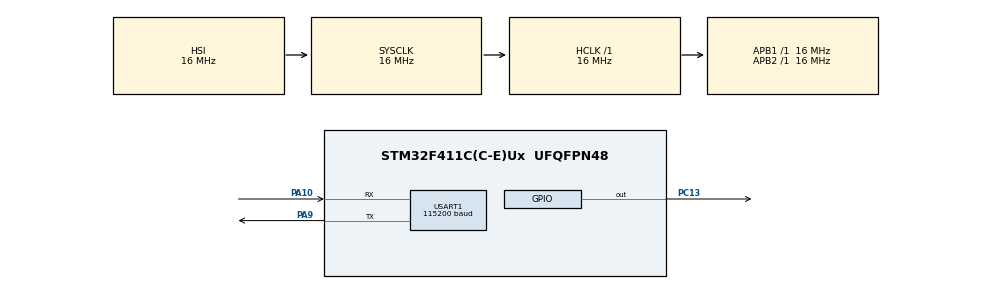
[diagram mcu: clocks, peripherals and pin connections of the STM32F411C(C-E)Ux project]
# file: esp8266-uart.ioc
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Dma.Request0=USART1_TX
Dma.USART1_TX.0.Direction=DMA_MEMORY_TO_PERIPH
Dma.USART1_TX.0.FIFOMode=DMA_FIFOMODE_DISABLE
Dma.USART1_TX.0.Instance=DMA2_Stream7
Dma.USART1_TX.0.MemDataAlignment=DMA_MDATAALIGN_BYTE
Dma.USART1_TX.0.MemInc=DMA_MINC_ENABLE
Dma.USART1_TX.0.Mode=DMA_CIRCULAR
Dma.USART1_TX.0.PeriphDataAlignment=DMA_PDATAALIGN_BYTE
Dma.USART1_TX.0.PeriphInc=DMA_PINC_DISABLE
Dma.USART1_TX.0.Priority=DMA_PRIORITY_LOW
Mcu.Family=STM32F4
Mcu.Name=STM32F411C(C-E)Ux
Mcu.Package=UFQFPN48
NVIC.DMA2_Stream7_IRQn=true\:0\:0\:false\:false\:true\:false\:true\:true
NVIC.PriorityGroup=NVIC_PRIORITYGROUP_4
NVIC.USART1_IRQn=true\:0\:0\:false\:false\:true\:true\:true\:true
PA10.Mode=Asynchronous
PA10.Signal=USART1_RX
PA9.Mode=Asynchronous
PA9.Signal=USART1_TX
PC13-ANTI_TAMP.PinState=GPIO_PIN_SET
PC13-ANTI_TAMP.Signal=GPIO_Output
ProjectManager.HeapSize=0x200
ProjectManager.StackSize=0x400
ProjectManager.TargetToolchain=STM32CubeIDE
RCC.AHBFreq_Value=16000000
RCC.APB1Freq_Value=16000000
RCC.APB2Freq_Value=16000000
RCC.CortexFreq_Value=16000000
RCC.HSE_VALUE=25000000
RCC.HSI_VALUE=16000000
RCC.LSE_VALUE=32768
RCC.SYSCLKFreq_VALUE=16000000
RCC.VCOOutputFreq_Value=192000000
USART1.BaudRate=115200
USART1.VirtualMode=VM_ASYNC
board=custom

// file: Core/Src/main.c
/* USER CODE BEGIN Header */
/**
  ******************************************************************************
  * @file           : main.c
  * @brief          : Main program body
  ******************************************************************************
  * @attention
  *
  * Copyright (c) 2025 STMicroelectronics.
  * All rights reserved.
  *
  * This software is licensed under terms that can be found in the LICENSE file
  * in the root directory of this software component.
  * If no LICENSE file comes with this software, it is provided AS-IS.
  *
  ******************************************************************************
  */
/* USER CODE END Header */
#include "main.h"

UART_HandleTypeDef huart1;
DMA_HandleTypeDef hdma_usart1_tx;

void SystemClock_Config(void);
static void MX_GPIO_Init(void);
static void MX_DMA_Init(void);
static void MX_USART1_UART_Init(void);

/* USER CODE BEGIN 0 */
int isSent = 1;
int countloop = 0;
int countinterrupt = 0;
int indx = 49;

uint8_t TxData[10240];
/* USER CODE END 0 */

int main(void)
{

  /* MCU Configuration--------------------------------------------------------*/

  /* Reset of all peripherals, Initializes the Flash interface and the Systick. */
  HAL_Init();

  /* Configure the system clock */
  SystemClock_Config();

  /* Initialize all configured peripherals */
  MX_GPIO_Init();
  MX_DMA_Init();
  MX_USART1_UART_Init();
  /* USER CODE BEGIN 2 */
  for (uint32_t i=0; i<10240; i++)
  {
	  TxData[i] = '0';
  }

	HAL_UART_Transmit_DMA(&huart1, TxData, 10240);
  /* USER CODE END 2 */

  /* Infinite loop */
  while (1)
  {

  }
}

void SystemClock_Config(void)
{
  RCC_OscInitTypeDef RCC_OscInitStruct = {0};
  RCC_ClkInitTypeDef RCC_ClkInitStruct = {0};

  /** Configure the main internal regulator output voltage
  */
  __HAL_RCC_PWR_CLK_ENABLE();
  __HAL_PWR_VOLTAGESCALING_CONFIG(PWR_REGULATOR_VOLTAGE_SCALE1);

  /** Initializes the RCC Oscillators according to the specified parameters
  * in the RCC_OscInitTypeDef structure.
  */
  RCC_OscInitStruct.OscillatorType = RCC_OSCILLATORTYPE_HSI;
  RCC_OscInitStruct.HSIState = RCC_HSI_ON;
  RCC_OscInitStruct.HSICalibrationValue = RCC_HSICALIBRATION_DEFAULT;
  RCC_OscInitStruct.PLL.PLLState = RCC_PLL_NONE;
  if (HAL_RCC_OscConfig(&RCC_OscInitStruct) != HAL_OK)
  {
    Error_Handler();
  }

  /** Initializes the CPU, AHB and APB buses clocks
  */
  RCC_ClkInitStruct.ClockType = RCC_CLOCKTYPE_HCLK|RCC_CLOCKTYPE_SYSCLK
                              |RCC_CLOCKTYPE_PCLK1|RCC_CLOCKTYPE_PCLK2;
  RCC_ClkInitStruct.SYSCLKSource = RCC_SYSCLKSOURCE_HSI;
  RCC_ClkInitStruct.AHBCLKDivider = RCC_SYSCLK_DIV1;
  RCC_ClkInitStruct.APB1CLKDivider = RCC_HCLK_DIV1;
  RCC_ClkInitStruct.APB2CLKDivider = RCC_HCLK_DIV1;

  if (HAL_RCC_ClockConfig(&RCC_ClkInitStruct, FLASH_LATENCY_0) != HAL_OK)
  {
    Error_Handler();
  }
}

static void MX_USART1_UART_Init(void)
{

  huart1.Instance = USART1;
  huart1.Init.BaudRate = 115200;
  huart1.Init.WordLength = UART_WORDLENGTH_8B;
  huart1.Init.StopBits = UART_STOPBITS_1;
  huart1.Init.Parity = UART_PARITY_NONE;
  huart1.Init.Mode = UART_MODE_TX_RX;
  huart1.Init.HwFlowCtl = UART_HWCONTROL_NONE;
  huart1.Init.OverSampling = UART_OVERSAMPLING_16;
  if (HAL_UART_Init(&huart1) != HAL_OK)
  {
    Error_Handler();
  }

}

static void MX_DMA_Init(void)
{

  /* DMA controller clock enable */
  __HAL_RCC_DMA2_CLK_ENABLE();

  /* DMA interrupt init */
  /* DMA2_Stream7_IRQn interrupt configuration */
  HAL_NVIC_SetPriority(DMA2_Stream7_IRQn, 0, 0);
  HAL_NVIC_EnableIRQ(DMA2_Stream7_IRQn);

}

static void MX_GPIO_Init(void)
{
  GPIO_InitTypeDef GPIO_InitStruct = {0};

  /* GPIO Ports Clock Enable */
  __HAL_RCC_GPIOC_CLK_ENABLE();
  __HAL_RCC_GPIOA_CLK_ENABLE();

  /*Configure GPIO pin Output Level */
  HAL_GPIO_WritePin(GPIOC, GPIO_PIN_13, GPIO_PIN_SET);

  /*Configure GPIO pin : PC13 */
  GPIO_InitStruct.Pin = GPIO_PIN_13;
  GPIO_InitStruct.Mode = GPIO_MODE_OUTPUT_PP;
  GPIO_InitStruct.Pull = GPIO_NOPULL;
  GPIO_InitStruct.Speed = GPIO_SPEED_FREQ_LOW;
  HAL_GPIO_Init(GPIOC, &GPIO_InitStruct);

}

/* USER CODE BEGIN 4 */
void HAL_UART_TxCpltCallback(UART_HandleTypeDef *huart)
{
	if (indx >= 60)
	{
		HAL_UART_DMAStop(&huart1);
	}

	for (uint32_t i = 5120; i < 10240; i++)
	{
		TxData[i] = indx;
	}
	indx++;

	isSent = 1;
	countinterrupt++;
}

void HAL_UART_TxHalfCpltCallback(UART_HandleTypeDef *huart)
{
	for (uint32_t i = 0; i < 5120; i++)
	{
		TxData[i] = indx;
	}
	indx++;
}
/* USER CODE END 4 */

void Error_Handler(void)
{
  __disable_irq();
  while (1)
  {
  }
}
